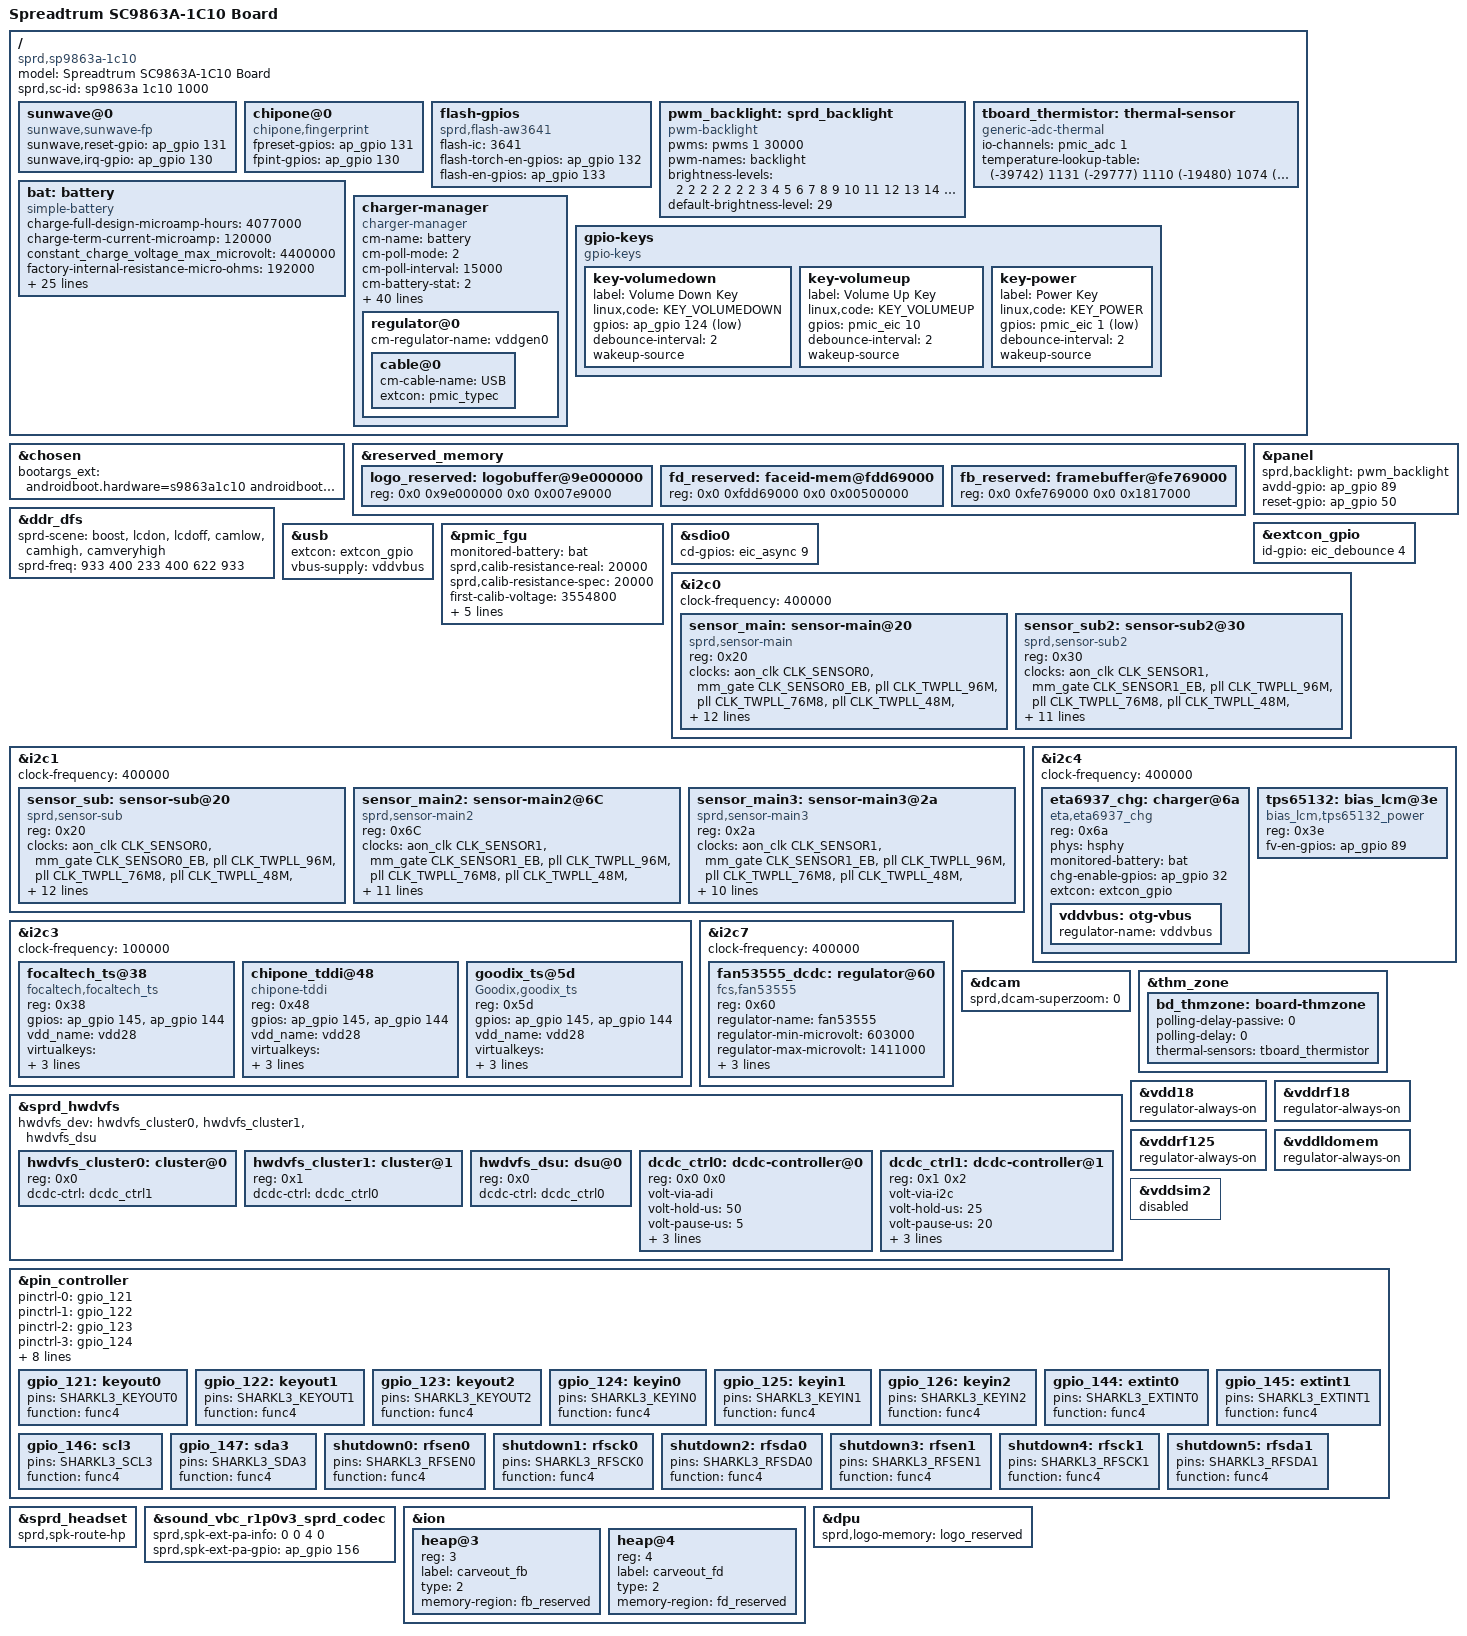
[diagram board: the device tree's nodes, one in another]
/dts-v1/;
/plugin/;

#include <dt-bindings/input/input.h>
#include <dt-bindings/gpio/gpio.h>
#include <dt-bindings/clock/sprd,sc9863a-clk.h>
#include "lcd/lcd_ft8006p_easyquick_mipi_hdp.dtsi"
#include "lcd/lcd_icnl9911_hlt_mipi_hdp.dtsi"
#include "lcd/lcd_dummy_mipi.dtsi"

/ {
	model = "Spreadtrum SC9863A-1C10 Board";
	compatible = "sprd,sp9863a-1c10", "sprd,sc9863a";
	sprd,sc-id = "sp9863a 1c10 1000";

	fragment {
		target-path = "/";
		__overlay__ {
			sunwave@0{
				compatible = "sunwave,sunwave-fp";
				sunwave,reset-gpio = <&ap_gpio 131 0 >;
				sunwave,irq-gpio = <&ap_gpio 130 0 >;
				//fpreset-gpios = <&ap_gpio 131 0 >;
				//fpint-gpios = <&ap_gpio 130 0 >;
			};

			chipone@0{
				compatible = "chipone,fingerprint";
				fpreset-gpios = <&ap_gpio 131 0 >;
				fpint-gpios = <&ap_gpio 130 0 >;
				/*fpint-gpios = <&ap_eic_async 13 0 >;*/
			};

			flash-gpios {
				compatible = "sprd,flash-aw3641";
				flash-ic = <3641>;
				flash-torch-en-gpios = <&ap_gpio 132 0>;
				flash-en-gpios = <&ap_gpio 133 0>;
			};

			pwm_backlight: sprd_backlight {
				compatible = "pwm-backlight";
				pwms = <&pwms 1 30000>;
				pwm-names = "backlight";
				brightness-levels = <
								  2   2   2   2
					  2   2   2   3   4   5   6   7   8   9
					 10  11  12  13  14  15  16  17  18  19
					 20  21  22  23  24  25  26  27  28  29
					 30  31  32  33  34  35  36  37  38  39
					 40  41  42  43  44  45  46  47  48  49
					 50  51  52  53  54  55  56  57  58  59
					 60  61  62  63  64  65  66  67  68  69
					 70  71  72  73  74  75  76  77  78  79
					 80  81  82  83  84  85  86  87  88  89
					 90  91  92  93  94  95  96  97  98  99
					100 101 102 103 104 105 106 107 108 109
					110 111 112 113 114 115 116 117 118 119
					120 121 122 123 124 125 126 127 128 129
					130 131 132 133 134 135 136 137 138 139
					140 141 142 143 144 145 146 147 148 149
					150 151 152 153 154 155 156 157 158 159
					160 161 162 163 164 165 166 167 168 169
					170 171 172 173 174 175 176 177 178 179
					180 181 182 183 184 185 186 187 188 189
					190 191 192 193 194 195 196 197 198 199
					200 201 202 203 204 205 206 207 208 209
					210 211 212 213 214 215 216 217 218 219
					220 221 222 223 224 225 226 227 228 229
					230 231 232 233 234 235 236 237 238 239
					240 241 242 243 244 245 246 247 248 249
					250 251
				>;
				default-brightness-level = <29>;
			};

			tboard_thermistor:thermal-sensor {
				compatible = "generic-adc-thermal";
				#thermal-sensor-cells = <0>;
				io-channels = <&pmic_adc 1>;
				io-channel-names = "sensor-channel";
				temperature-lookup-table = <	(-39742) 1131
								(-29777) 1110
								(-19480) 1074
								(-4679) 983
								10110 838
								24805 654
								44922 413
								54903 316
								64895 238
								74884 178
								84883 133
								94883 100
								104880 75
								114889 57
								124872 43 >;
			};

			bat: battery {
				compatible = "simple-battery";
				charge-full-design-microamp-hours = <4077000>;
				charge-term-current-microamp = <120000>;
				constant_charge_voltage_max_microvolt = <4400000>;
				factory-internal-resistance-micro-ohms = <192000>;
				voltage-min-design-microvolt = <3450000>;
				ocv-capacity-celsius = <20>;
				ocv-capacity-table-0 = <4382000 100>, <4320000 95>, <4261000 90>,
							<4203000 85>, <4148000 80>, <4094000 75>,
							<4049000 70>, <3991000 65>, <3952000 60>,
							<3898000 55>, <3859000 50>, <3832000 45>,
							<3810000 40>, <3793000 35>, <3779000 30>,
							<3765000 25>, <3747000 20>, <3724000 15>,
							<3693000 10>, <3681000 5>, <3400000 0>;
				voltage-temp-table = <1300000 700>, <1194000 750>, <1084000 800>,
							<976000 850>, <868000 900>, <765000 950>,
							<660000 1000>, <580000 1050>, <501000 1100>,
							<431000 1150>, <369000 1200>, <316000 1250>,
							<270000 1300>, <231000 1350>, <198000 1400>,
							<169000 1450>, <145000 1500>, <125000 1550>,
							<108000 1600>, <94000 1650>, <81000 1700>;
				capacity-temp-table = <45 100>, <25 100>, <10 98>, <0 91>, <(-10) 82>, <(-20) 53>;
				resistance-temp-table = <45 70>, <25 100>, <10 275>, <0 571>, <(-10) 631>, <(-20) 732>;
				charge-sdp-current-microamp = <450000 500000>;
				charge-dcp-current-microamp = <2500000 3000000>;
				charge-cdp-current-microamp = <1150000 1150000>;
				charge-unknown-current-microamp = <450000 500000>;
			};

			charger-manager {
				compatible = "charger-manager";
				cm-name = "battery";
				cm-poll-mode = <2>;
				cm-poll-interval = <15000>;
				cm-battery-stat = <2>;

				cm-fullbatt-vchkdrop-ms = <30000>;
				cm-fullbatt-vchkdrop-volt = <60000>;
				cm-fullbatt-voltage = <4350000>;
				cm-fullbatt-current = <120000>;
				cm-fullbatt-capacity = <100>;

				cm-chargers = "eta6937_charger";
				cm-fuel-gauge = "sc27xx-fgu";

				/* in deci centigrade */
				cm-battery-cold = <200>;
				cm-battery-cold-in-minus;
				cm-battery-hot = <800>;
				cm-battery-temp-diff = <100>;

				/* Allow charging for 6hr */
				cm-charging-max = <21600000>;
				/* recovery charging after stop charging 3hr */
				cm-discharging-max = <10800000>;

				/* the interval to feed charger watchdog */
				cm-wdt-interval = <60>;

				/* drop voltage in microVolts to allow shutdown */
				cm-shutdown-voltage = <3100000>;

				/* when 99% of the time is exceeded, it will be forced to 100% */
				cm-tickle-time-out = <1500>;

				/* how much time to allow capacity change */
				cm-one-cap-time = <30>;

				/* when the safe charging voltage is exceeded, stop charging */
				cm-charge-voltage-max = <6500000>;
				/* drop voltage in microVolts to restart charging */
				cm-charge-voltage-drop = <700000>;
				cm-thermal-zone = "board-thmzone";
				cm-dcp-jeita-temp-table = <1000 1020 0 4400000>,
					 <1150 1170 800000 4400000>,
					 <1450 1430 2000000 4400000>,
					 <1550 1530 500000 4100000>;
				cm-sdp-jeita-temp-table = <1000 1030 0 4400000>,
					<1150 1180 500000 4400000>,
					<1450 1420 500000 4400000>,
					<1600 1570 500000 4100000>;
				cm-cdp-jeita-temp-table = <1000 1030 0 4400000>,
					<1150 1180 700000 4400000>,
					<1450 1420 1150000 4400000>,
					<1600 1570 700000 4100000>;
				cm-unknown-jeita-temp-table = <1000 1030 0 4400000>,
					<1150 1180 500000 4400000>,
					<1450 1420 500000 4400000>,
					<1600 1570 500000 4100000>;

				monitored-battery = <&bat>;

				cm-cap-remap-table = <1 2 3>, <2 3 2>, <98 99 2>, <99 100 3>;

				regulator@0 {
					cm-regulator-name = "vddgen0";
					cable@0 {
						cm-cable-name = "USB";
						extcon = <&pmic_typec>;
					};
				};
			};

			gpio-keys {
				compatible = "gpio-keys";

				key-volumedown {
					label = "Volume Down Key";
					linux,code = <KEY_VOLUMEDOWN>;
					gpios = <&ap_gpio 124 GPIO_ACTIVE_LOW>;
					debounce-interval = <2>;
					wakeup-source;
				};

				key-volumeup {
					label = "Volume Up Key";
					linux,code = <KEY_VOLUMEUP>;
					gpios = <&pmic_eic 10 GPIO_ACTIVE_HIGH>;
					debounce-interval = <2>;
					wakeup-source;
				};

				key-power {
					label = "Power Key";
					linux,code = <KEY_POWER>;
					gpios = <&pmic_eic 1 GPIO_ACTIVE_LOW>;
					debounce-interval = <2>;
					wakeup-source;
				};
			};
		};
	};
};

&chosen {
	bootargs_ext = "androidboot.hardware=s9863a1c10 androidboot.dtbo_idx=0";
};

&reserved_memory {

	logo_reserved: logobuffer@9e000000{
		reg = <0x0 0x9e000000 0x0 0x007e9000>;
	};

	fd_reserved: faceid-mem@fdd69000{
		reg = <0x0 0xfdd69000 0x0 0x00500000>;
	};

	fb_reserved: framebuffer@fe769000 {
		reg = <0x0 0xfe769000 0x0 0x1817000>;
	};
};

&panel {
	sprd,backlight = <&pwm_backlight>;
	avdd-gpio = <&ap_gpio 89 GPIO_ACTIVE_HIGH>;
	reset-gpio = <&ap_gpio 50 GPIO_ACTIVE_HIGH>;
};

&ddr_dfs {
	sprd-scene = "boost", "lcdon", "lcdoff", "camlow",
			"camhigh", "camveryhigh";
	sprd-freq = <933 400 233 400 622 933>;
};

&extcon_gpio {
	id-gpio = <&eic_debounce 4 GPIO_ACTIVE_HIGH>;
};

&usb {
	extcon = <&extcon_gpio>;
	vbus-supply = <&vddvbus>;
};

&pmic_fgu {
	monitored-battery = <&bat>;
	sprd,calib-resistance-real = <20000>;
	sprd,calib-resistance-spec = <20000>;
	first-calib-voltage = <3554800>;
	first-calib-capacity = <50>;
	fgu-capacity-track;
	fullbatt-track-end-vol = <4345>;
	fullbatt-track-end-cur = <130>;
	phys = <&hsphy>;
};

&sdio0 {
	cd-gpios = <&eic_async 9 1>;
};

&i2c0 {
	status = "okay";
	clock-frequency = <400000>;

	sensor_main: sensor-main@20 {
		compatible = "sprd,sensor-main";
		reg = <0x20>;
		clock-names = "clk_src","sensor_eb",
			"clk_96m","clk_76m8",
			"clk_48m","clk_26m";
		clocks = <&aon_clk CLK_SENSOR0>, <&mm_gate CLK_SENSOR0_EB>,
			<&pll CLK_TWPLL_96M>,<&pll CLK_TWPLL_76M8>,
			<&pll CLK_TWPLL_48M>,<&ext_26m>;
		vddio-supply = <&vddcamio>;
		vddcama-supply = <&vddcama>;
		vddcamd-supply = <&vddcamd>;
		vddcammot-supply = <&vddcammot>;
		avdd-gpios=<&ap_gpio 62 0>;
		mipi-switch-mode-gpios= <&ap_gpio 30 1>;
		mipi-switch-en-gpios= <&ap_gpio 29 0>;
		sprd,phyid = <1>;
		csi = <&csi0>;
		reset-gpios = <&ap_gpio 44 0>;
		power-down-gpios = <&ap_gpio 46 0>;
	};

	sensor_sub2: sensor-sub2@30 {
		compatible = "sprd,sensor-sub2";
		reg = <0x30>;
		clock-names = "clk_src","sensor_eb",
			"clk_96m","clk_76m8",
			"clk_48m","clk_26m";
		clocks = <&aon_clk CLK_SENSOR1>, <&mm_gate CLK_SENSOR1_EB>,
			<&pll CLK_TWPLL_96M>,<&pll CLK_TWPLL_76M8>,
			<&pll CLK_TWPLL_48M>,<&ext_26m>;
		vddio-supply = <&vddcamio>;
		vddcama-supply = <&vddcama>;
		vddcamd-supply = <&vddcamd>;
		vddcammot-supply = <&vddcammot>;
		sprd,phyid = <2>;
		csi = <&csi1>;
		iovdd-gpios=<&ap_gpio 15 0>;
		dvdd-gpios=<&ap_gpio 5 0>;
		reset-gpios = <&ap_gpio 16 0>;
		power-down-gpios = <&ap_gpio 57 0>;
	};
};

&i2c1 {
	status = "okay";
	clock-frequency = <400000>;

	sensor_sub: sensor-sub@20 {
		compatible = "sprd,sensor-sub";
		reg = <0x20>;
		clock-names = "clk_src","sensor_eb",
			"clk_96m","clk_76m8",
			"clk_48m","clk_26m";
		clocks = <&aon_clk CLK_SENSOR0>, <&mm_gate CLK_SENSOR0_EB>,
			<&pll CLK_TWPLL_96M>,<&pll CLK_TWPLL_76M8>,
			<&pll CLK_TWPLL_48M>,<&ext_26m>;
		vddio-supply = <&vddcamio>;
		vddcama-supply = <&vddcama>;
		vddcamd-supply = <&vddcamd>;
		vddcammot-supply = <&vddcammot>;
		sprd,phyid = <1>;
		csi = <&csi0>;
		avdd-gpios=<&ap_gpio 62 0>;
		mipi-switch-mode-gpios= <&ap_gpio 30 0>;
		mipi-switch-en-gpios= <&ap_gpio 29 0>;
		reset-gpios = <&ap_gpio 41 0>;
		power-down-gpios = <&ap_gpio 40 0>;
	};

	sensor_main2: sensor-main2@6C {
		compatible = "sprd,sensor-main2";
		reg = <0x6C>;
		clock-names = "clk_src","sensor_eb",
			"clk_96m","clk_76m8",
			"clk_48m","clk_26m";
		clocks = <&aon_clk CLK_SENSOR1>, <&mm_gate CLK_SENSOR1_EB>,
			<&pll CLK_TWPLL_96M>,<&pll CLK_TWPLL_76M8>,
			<&pll CLK_TWPLL_48M>,<&ext_26m>;
		vddio-supply = <&vddcamio>;
		vddcama-supply = <&vddcama>;
		vddcamd-supply = <&vddcamd>;
		vddcammot-supply = <&vddcammot>;
		sprd,phyid = <4>;
		csi = <&csi1>;
		iovdd-gpios=<&ap_gpio 15 0>;
		dvdd-gpios=<&ap_gpio 5 0>;
		reset-gpios = <&ap_gpio 56 0>;
		power-down-gpios = <&ap_gpio 59 0>;
	};

	sensor_main3: sensor-main3@2a {
		compatible = "sprd,sensor-main3";
		reg = <0x2a>;
		clock-names = "clk_src","sensor_eb",
			"clk_96m","clk_76m8",
			"clk_48m","clk_26m";
		clocks = <&aon_clk CLK_SENSOR1>, <&mm_gate CLK_SENSOR1_EB>,
			<&pll CLK_TWPLL_96M>,<&pll CLK_TWPLL_76M8>,
			<&pll CLK_TWPLL_48M>,<&ext_26m>;
		vddio-supply = <&vddcamio>;
		vddcama-supply = <&vddcama>;
		vddcamd-supply = <&vddcamd>;
		vddcammot-supply = <&vddcammot>;
		sprd,phyid = <3>;
		csi = <&csi1>;
		dvdd-gpios=<&ap_gpio 142 0>;
		reset-gpios = <&ap_gpio 45 0>;
		power-down-gpios = <&ap_gpio 47 0>;
	};
};

&i2c3 {
	status = "okay";
	clock-frequency = <100000>;
	focaltech_ts@38 {
		compatible = "focaltech,focaltech_ts";
		reg = <0x38>;
		gpios = <&ap_gpio 145 0
			&ap_gpio 144 0>;
		vdd_name = "vdd28";
		virtualkeys = <80 900 60 40
				240 900 60 40
				400 900 60 40>;
		TP_MAX_X = <720>;
		TP_MAX_Y = <1440>;
	};
	chipone_tddi@48 {
		compatible = "chipone-tddi";
		reg = <0x48>;
		gpios = <&ap_gpio 145 0
			&ap_gpio 144 0>;
		vdd_name = "vdd28";
		virtualkeys = <80 900 60 40
				240 900 60 40
				400 900 60 40>;
		TP_MAX_X = <720>;
		TP_MAX_Y = <1440>;
	};

	goodix_ts@5d {
		compatible = "Goodix,goodix_ts";
		reg = <0x5d>;
		gpios = <&ap_gpio 145 0
			&ap_gpio 144 0>;
		vdd_name = "vdd28";
		virtualkeys = <40 1350 60 40
			120 1350 60 40
			200 1350 60 40>;
		TP_MAX_X = <720>;
		TP_MAX_Y = <1440>;
	};
};

&i2c4 {
	status = "okay";
	clock-frequency = <400000>;

	eta6937_chg: charger@6a {
		compatible = "eta,eta6937_chg";
		reg = <0x6a>;
		phys = <&hsphy>;
		monitored-battery = <&bat>;
		chg-enable-gpios = <&ap_gpio 32 0>;
		extcon = <&extcon_gpio>;
		vddvbus:otg-vbus {
			regulator-name = "vddvbus";
		};
	};

	tps65132: bias_lcm@3e {/*WW6 just for fs170 lcm 5v*/
		compatible = "bias_lcm,tps65132_power";
		reg = <0x3e>;
		fv-en-gpios = <&ap_gpio 89 0>;
	};
};

&i2c7 {
	status = "okay";
	clock-frequency = <400000>;

	fan53555_dcdc: regulator@60 {
		compatible = "fcs,fan53555";
		reg = <0x60>;
		regulator-name = "fan53555";
		regulator-min-microvolt = <603000>;
		regulator-max-microvolt = <1411000>;
		regulator-ramp-delay = <64000>;
		regulator-always-on;
		fcs,suspend-voltage-selector = <1>;
	};
};

&sdio0 {
	cd-gpios = <&eic_async 9 0>;/*ww6 sd hot plut */
};

&dcam {
	status = "okay";
	sprd,dcam-superzoom = <0>;
};

&sprd_hwdvfs {
	hwdvfs_dev = <&hwdvfs_cluster0>,
		<&hwdvfs_cluster1>,
		<&hwdvfs_dsu>;

	hwdvfs_cluster0: cluster@0 {
		reg = <0x0>;
		dcdc-ctrl = <&dcdc_ctrl1>;
	};

	hwdvfs_cluster1: cluster@1 {
		reg = <0x1>;
		dcdc-ctrl = <&dcdc_ctrl0>;
	};

	hwdvfs_dsu: dsu@0 {
		reg = <0x0>;
		dcdc-ctrl = <&dcdc_ctrl0>;
	};

	dcdc_ctrl0: dcdc-controller@0 {
		reg = <0x0 0x0>;
		volt-via-adi;
		volt-hold-us = <50>;
		volt-pause-us = <5>;
		volt-timeout-us = <800>;
		volt-stable-us  = <5>;
		volt-max-step-microvolt = <25000>;
	};

	dcdc_ctrl1: dcdc-controller@1 {
		reg = <0x1 0x2>;
		volt-via-i2c;
		volt-hold-us = <25>;
		volt-pause-us = <20>;
		volt-timeout-us = <800>;
		volt-stable-us  = <25>;
		volt-max-step-microvolt = <1200004>;
	};
};

&thm_zone {
	bd_thmzone: board-thmzone {
		polling-delay-passive = <0>;
		polling-delay = <0>;
		thermal-sensors = <&tboard_thermistor>;
	};
};

&vdd18 {
	regulator-always-on;
};

&vddrf18 {
	regulator-always-on;
};

&vddrf125 {
	regulator-always-on;
};

&vddldomem {
	regulator-always-on;
};

&vddsim2 {
	status = "disabled";
};

&pin_controller {
	pinctrl-names =
	/* keyout0 ~ keyout2 */
	"gpio_121", "gpio_122", "gpio_123",
	/* keyin0 ~ keyin2 */
	"gpio_124", "gpio_125", "gpio_126",
	/* extint0, extint1, scl3, sda3 */
	"gpio_144", "gpio_145", "gpio_146", "gpio_147",
	/* Note:If create a new board,need to add the shutdown node */
	"shutdown";
	pinctrl-0 = <&gpio_121>;
	pinctrl-1 = <&gpio_122>;
	pinctrl-2 = <&gpio_123>;
	pinctrl-3 = <&gpio_124>;
	pinctrl-4 = <&gpio_125>;
	pinctrl-5 = <&gpio_126>;
	pinctrl-6 = <&gpio_144>;
	pinctrl-7 = <&gpio_145>;
	pinctrl-8 = <&gpio_146>;
	pinctrl-9 = <&gpio_147>;
	pinctrl-10 = <&shutdown0
			&shutdown1
			&shutdown2
			&shutdown3
			&shutdown4
			&shutdown5>;

	gpio_121: keyout0 {
		pins = "SHARKL3_KEYOUT0";
		function = "func4";
	};

	gpio_122: keyout1 {
		pins = "SHARKL3_KEYOUT1";
		function = "func4";
	};

	gpio_123: keyout2 {
		pins = "SHARKL3_KEYOUT2";
		function = "func4";
	};

	gpio_124: keyin0 {
		pins = "SHARKL3_KEYIN0";
		function = "func4";
	};

	gpio_125: keyin1 {
		pins = "SHARKL3_KEYIN1";
		function = "func4";
	};

	gpio_126: keyin2 {
		pins = "SHARKL3_KEYIN2";
		function = "func4";
	};

	gpio_144: extint0 {
		pins = "SHARKL3_EXTINT0";
		function = "func4";
	};

	gpio_145: extint1 {
		pins = "SHARKL3_EXTINT1";
		function = "func4";
	};

	gpio_146: scl3 {
		pins = "SHARKL3_SCL3";
		function = "func4";
	};

	gpio_147: sda3 {
		pins = "SHARKL3_SDA3";
		function = "func4";
	};

	shutdown0: rfsen0 {
		pins = "SHARKL3_RFSEN0";
		function = "func4";
	};

	shutdown1: rfsck0 {
		pins = "SHARKL3_RFSCK0";
		function = "func4";
	};

	shutdown2: rfsda0 {
		pins = "SHARKL3_RFSDA0";
		function = "func4";
	};

	shutdown3: rfsen1 {
		pins = "SHARKL3_RFSEN1";
		function = "func4";
	};

	shutdown4: rfsck1 {
		pins = "SHARKL3_RFSCK1";
		function = "func4";
	};

	shutdown5: rfsda1 {
		pins = "SHARKL3_RFSDA1";
		function = "func4";
	};
};

&sprd_headset {
	status = "okay";
	sprd,spk-route-hp;
};

&sound_vbc_r1p0v3_sprd_codec {
	status = "okay";

	/*ext_control_type, hook selection, mode, gpio share*/
	sprd,spk-ext-pa-info = <0 0 4 0>;
	sprd,spk-ext-pa-gpio = <&ap_gpio 156 0>;
};

&ion {
	heap@3 {
			reg = <3>;
			label = "carveout_fb";
			type = <2>;
			memory-region = <&fb_reserved>;
	};

	heap@4 {
			reg = <4>;
			label = "carveout_fd";
			type = <2>;
			memory-region = <&fd_reserved>;
	};
};

&dpu {
	sprd,logo-memory = <&logo_reserved>;

};
